# S32R372 register map
Vendor: Freescale Semiconductor, Inc.; Series: Qorivva; File version: 1.6
Registers are 32-bit, read-write, reset 0x0 unless marked. A register's access mark holds for its fields unless they carry their own. Offsets are from the block's base; [hi:lo] are bit positions; lines under a group give offsets from that group; {n}, {i} and the like mark numbered series; 'fields as' and 'values as' point back to an identical list.

## MC_PCU — PCU
Base 0xFFFA0000; register names take the prefix MC_PCU_
0x40 PSTAT ro reset 0x1 — Power Domain Status Register

## IRCOSC
Base 0xFFFB0000; register names take the prefix IRCOSC_
0x00 CTL — IRCOSC Control Register
  [20:16] USER_TRIM — User trimming bits with respect to nominal factory frequency The MSB of the USER_TRIM bits is used to determine whether the frequency will be increased or decreased

## PLLDIG
Base 0xFFFB0100; register names take the prefix PLLDIG_
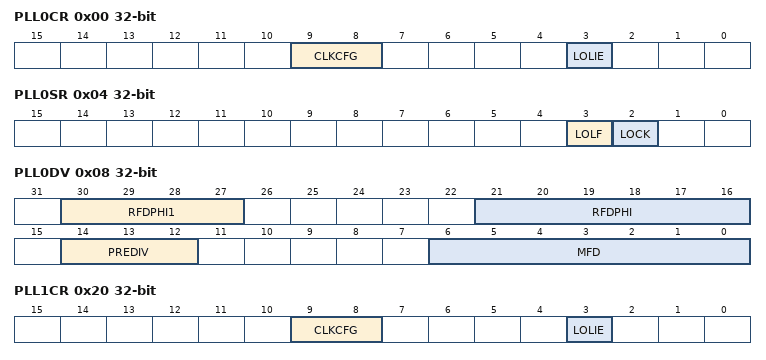
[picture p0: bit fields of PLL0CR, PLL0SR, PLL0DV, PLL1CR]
0x00 PLL0CR — PLLDIG PLL0 Control Register
  [9:8] CLKCFG ro — Clock Configuration
    0=Bypass mode with PLL off; 3=Normal mode with PLL running
  [3] LOLIE — Loss-of-lock interrupt enable.
    0=Ignore loss-of-lock. Interrupt not requested.; 1=Enable interrupt request upon loss-of-lock
0x04 PLL0SR — PLLDIG PLL0 Status Register
  [3] LOLF — Loss-of-lock flag.
    0=No loss of lock detected. Interrupt service not requested.; 1=Loss of lock detected. Interrupt service requested.
  [2] LOCK ro — Lock status bit
    0=PLL is unlocked; 1=PLL is locked
0x08 PLL0DV — PLLDIG PLL0 Divider Register
  [30:27] RFDPHI1 — PHI1 reduced frequency divider.
  [21:16] RFDPHI — PHI reduced frequency divider.
  [14:12] PREDIV — Input clock predivider.
    0=Clock inhibit; {v}=Divide by {v} (v=1..7)
  [6:0] MFD — Loop multiplication factor divider.
0x20 PLL1CR — PLLDIG PLL1 Control Register
  fields as PLL0CR
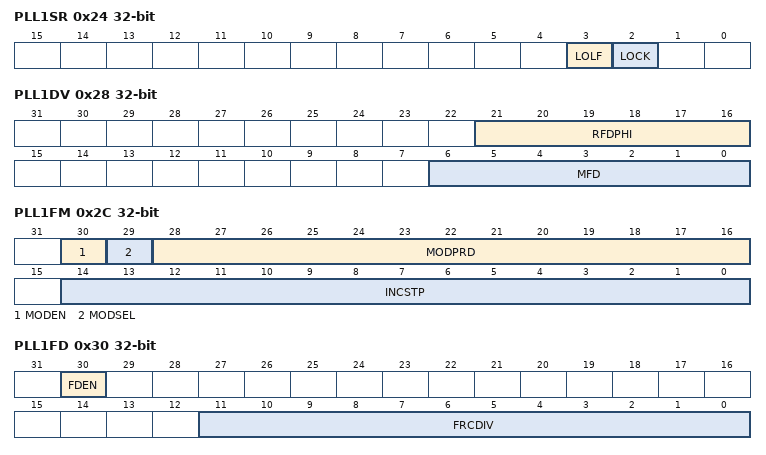
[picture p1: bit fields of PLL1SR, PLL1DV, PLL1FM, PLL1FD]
0x24 PLL1SR — PLLDIG PLL1 Status Register
  fields as PLL0SR
0x28 PLL1DV — PLLDIG PLL1 Divider Register
  [21:16] RFDPHI — PHI reduced frequency divider.
  [6:0] MFD — Loop multiplication factor divider.
0x2C PLL1FM — PLLDIG PLL1 Frequency Modulation Register
  [30] MODEN — Modulation enable.
    0=Frequency modulation disabled; 1=Frequency modulation enabled
  [29] MODSEL — Modulation selection.
    0=Centre Spread Modulation - Modulation centred around nominal frequency; 1=Down Spread Modulation - Modulation spread below nominal frequency
  [28:16] MODPRD — Modulation period.
  [14:0] INCSTP — Increment step.
0x30 PLL1FD — PLLDIG PLL1 Fractional Divide Register
  [30] FDEN — Fractional Divide Enable
    0=Fractional divide disabled; 1=Fractional divide enabled
  [11:0] FRCDIV — Fractional divide input

## PASS
Base 0xFFFF4000; register names take the prefix PASS_
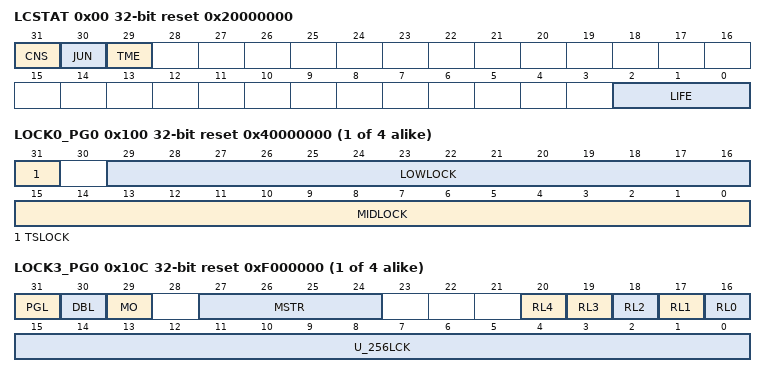
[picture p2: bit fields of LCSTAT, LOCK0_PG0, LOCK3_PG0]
0x00 LCSTAT ro reset 0x20000000 — Life Cycle Status Register
  [31] CNS — This field indicates whether the DCF Censorship client has been written with a DCF record to 0x55AA or if the DCF Censorship client contains any other value than 0x55AA
    1=DCF Censorship Client value is anything other than 0x55AA; 0=DCF Censorship client value is 0x55AA
  [30] JUN — This field indicates whether the device has been temporarily uncensored
  [29] TME — Test Mode enable
    0=Test mode cannot be enabled; 1=Test mode can be enabled with test mode password
  [2:0] LIFE — The life cycle setting is manipulated externally (SSCM). Pass displays a 3-bit input life cycle
    0=Failure Analysis; 2=OEM Production; 3=Customer Delivery; 6=MCU Production; 7=In Field
0x08 CHSEL — Challenge Selector Register
  [1:0] GRP — Password Group to unlock
    {v}=Password Group {v} (v=0..3)
0x10 CSTAT ro — Challenge Status Register
  [3:0] CMST — ID of the master which has last written the CHSEL register
{0x20+4i} CIN{i} (i=0..7) wo — Challenge Input Register
  [31:0] PW32 — 32 bits of the 256-bit password challenge. Only 32-bit writes may be used.
{0x100+0x10*i} LOCK0_PG{i} (i=0..3) reset 0x40000000 — Password Group n - Lock 0 Status Register
  [31] TSLOCK — UTest NVM Lock
  [29:16] LOWLOCK — Low Block Lock
  [15:0] MIDLOCK — Mid Block Lock
{0x104+0x10*i} LOCK1_PG{i} (i=0..3) — Password Group n - Lock 1 Status Register
  [15:0] HIGHLOCK — High Block Lock
{0x108+0x10*i} LOCK2_PG{i} (i=0..3) reset 0xFFFFFFFF — Password Group n - Lock 2 Status Register
  [31:0] L_256LCK — Lower 256KByte Block Lock
{0x10C+0x10*i} LOCK3_PG{i} (i=0..3) reset 0xF000000 — Password Group n - Lock 3 Status Register
  [31] PGL — Password Group Lock
    0=Password group registers are unlocked. All four registers in the Password group may be read and written without restriction.; 1=Password group registers are locked. Writes to the password group registers have no effect. Read accesses work normally. (If life cycle is Customer Delivery or earlier, this bit has no effect and the registers are always unlocked.)
  [30] DBL — Debug Interface Lock
    0=Debug interface is unlocked. Accessed to all JTAG clients is allowed; 1=Debug interface is locked. Only access to JTAG password challenge register is possible. Access to all other JTAG clients is blocked
  [29] MO — Master Only.
    0=All masters can modify the passgroup settings if PGL is cleared; 1=Only the Master which unlocked the passgroup can change the passgroup settings
  [27:24] MSTR ro — Master Access
  [20] RL4 — Read Lock Regison 4 lock bit
    0=Region 4 is not protected; 1=Region 4 is protected
  [n+16] RL{n} (n=0..3) — Region {n} is protected
    0=Region {n} is not protected; 1=Region {n} is protected
  [15:0] U_256LCK — Upper 256 KB Block Lock

## SSCM
Base 0xFFFF8000; register names take the prefix SSCM_
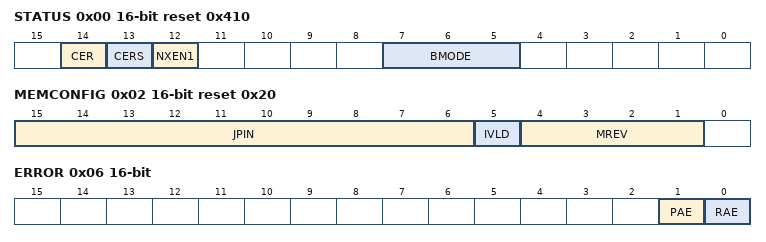
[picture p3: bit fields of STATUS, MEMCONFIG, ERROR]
0x00 STATUS 16-bit reset 0x410 — SSCM System Status
  [14] CER — Configuration Error
    0=No configuration problem detected by the SSCM; 1=Device configuration is not correct
  [13] CERS — Configuration Error for Safe DCF Clients
    values as CER
  [12] NXEN1 ro — Processor 1 Nexus enable status
    0=Processor 1 Nexus disabled; 1=Processor 1 Nexus enabled
  [7:5] BMODE ro — Device Boot Mode
    1=CAN Serial Boot Loader; 2=SCI Serial Boot Loader; 3=Single Chip(no Boot flash memory)
0x02 MEMCONFIG 16-bit ro reset 0x20 — SSCM System Memory and ID Register
  [15:6] JPIN — JTAG Part ID Number Reset value reflects the JTAG part ID of the device.
  [5] IVLD — Instruction flash memory Valid
    0=Instruction Flash is not accessible; 1=Instruction Flash is accessible
  [4:1] MREV — Minor Mask Revision
0x06 ERROR 16-bit — SSCM Error Configuration Register
  [1] PAE — Peripheral Bus Abort Enable.
    0=Illegal accesses to non-existing peripherals do not produce a Prefetch or Data Abort exception; 1=Illegal accesses to non-existing peripherals produce a Prefetch or Data Abort exception
  [0] RAE — Register Bus Abort Enable.
    0=Illegal accesses to peripherals do not produce a Prefetch or Data Abort exception; 1=Illegal accesses to peripherals produce a Prefetch or Data Abort exception
0x28 PSA ro — Processor Start Address Register
  [31:0] SADR — Processor Start Address
0x34 LCSTAT ro — Life Cycle Status Register
  [2:0] LC — Life Cycle
    0=Failure Analysis; 2=OEM Production; 3=Customer Delivery; 6=MCU Production; 7=In Field
